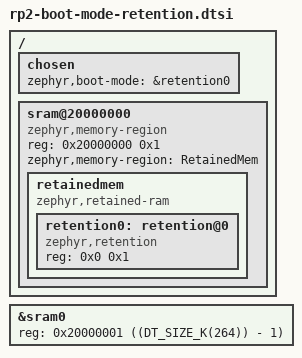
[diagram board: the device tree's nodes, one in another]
/*
 * Copyright (c) 2025 The ZMK Contributors
 *
 * SPDX-License-Identifier: MIT
 */

/* Be sure we don't overlap the reserved byte for storing the boot-mode */
&sram0 {
    reg = <0x20000001 ((DT_SIZE_K(264)) - 1)>;
};

/ {
    chosen {
        zephyr,boot-mode = &retention0;
    };

    /* We place retained mem at the start, to avoid the bootrom
       from clobbering our RAM */
    sram@20000000 {
        compatible = "zephyr,memory-region", "mmio-sram";
        reg = <0x20000000 0x1>;
        zephyr,memory-region = "RetainedMem";
        status = "okay";

        retainedmem {
             compatible = "zephyr,retained-ram";
             status = "okay";
             #address-cells = <1>;
             #size-cells = <1>;

             retention0: retention@0 {
                 compatible = "zephyr,retention";
                 status = "okay";
                 reg = <0x0 0x1>;
             };
        };
    };
};

